# STM8S003K3 register map
Vendor: STMicroelectronics; Series: STM8S/STM8AF, low density; File version: 1.0
CPU: other r1p0, big endian, no MPU, no FPU, 4 interrupt priority bits
Registers are 8-bit, read-write, reset 0x0 unless marked. A register's access mark holds for its fields unless they carry their own. Offsets are from the block's base; [hi:lo] are bit positions; {n}, {i} and the like mark numbered series.

## CPU
Base 0x00007F00
0x00 A — Accumulator
0x01 PCE — Program counter extended
0x02 PCH — Program counter high
0x03 PCL — Program counter low
0x04 XH — X index register high
0x05 XL — X index register low
0x06 YH — Y index register high
0x07 YL — Y index register low
0x08 SPH reset 0x3 — Stack pointer high
0x09 SPL reset 0xFF — Stack pointer low
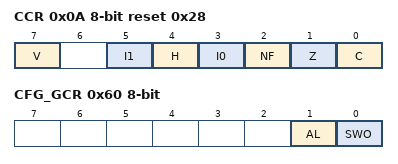
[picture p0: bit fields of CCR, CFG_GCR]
0x0A CCR reset 0x28 — Condition code register
  [7] V, [5] I1, [4] H, [3] I0, [2] NF, [1] Z, [0] C
0x60 CFG_GCR — Global configuration register
  [1] AL, [0] SWO

## DM
Base 0x00007F90
0x00 BK1RE reset 0xFF — DM breakpoint 1 register extended byte
0x01 BK1RH reset 0xFF — DM breakpoint 1 register high byte
0x02 BK1RL reset 0xFF — DM breakpoint 1 register low byte
0x03 BK2RE reset 0xFF — DM breakpoint 2 register extended byte
0x04 BK2RH reset 0xFF — DM breakpoint 2 register high byte
0x05 BK2RL reset 0xFF — DM breakpoint 2 register low byte
0x06 CR1 — DM debug module control register 1
0x07 CR2 — DM debug module control register 2
0x08 CSR1 reset 0x10 — DM debug module control/status register 1
0x09 CSR2 — DM debug module control/status register 2
0x0A ENFCTR reset 0xFF — DM enable function register

## FLASH
Base 0x0000505A
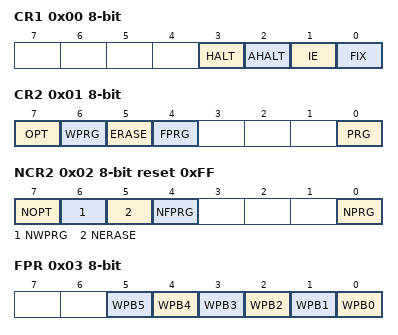
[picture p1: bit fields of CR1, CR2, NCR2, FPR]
0x00 CR1 — Flash control register 1
  [3] HALT, [2] AHALT, [1] IE, [0] FIX
0x01 CR2 — Flash control register 2
  [7] OPT, [6] WPRG, [5] ERASE, [4] FPRG, [0] PRG
0x02 NCR2 reset 0xFF — Flash complementary control register 2
  [7] NOPT, [6] NWPRG, [5] NERASE, [4] NFPRG, [0] NPRG
0x03 FPR — Flash protection register
  [n] WPB{n} (n=0..5)
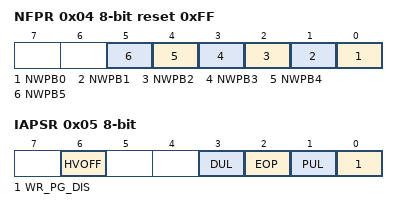
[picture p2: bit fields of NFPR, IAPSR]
0x04 NFPR reset 0xFF — Flash complementary protection register
  [n] NWPB{n} (n=0..5)
0x05 IAPSR — Flash in-application programming status register
  [6] HVOFF, [3] DUL, [2] EOP, [1] PUL, [0] WR_PG_DIS
0x08 PUKR — Flash program memory unprotection register
  [7:0] MASS_PRG
0x0A DUKR — Data EEPROM unprotection register
  [7:0] MASS_DATA

## I2C
Base 0x00005210
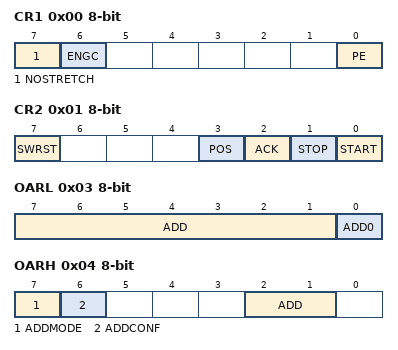
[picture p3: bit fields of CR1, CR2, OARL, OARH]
0x00 CR1 — I2C control register 1
  [7] NOSTRETCH, [6] ENGC, [0] PE
0x01 CR2 — I2C control register 2
  [7] SWRST, [3] POS, [2] ACK, [1] STOP, [0] START
0x02 FREQR — I2C frequency register
  [5:0] FREQ
0x03 OARL — I2C Own address register low
  [7:1] ADD, [0] ADD0
0x04 OARH — I2C Own address register high
  [7] ADDMODE, [6] ADDCONF, [2:1] ADD
0x06 DR — I2C data register
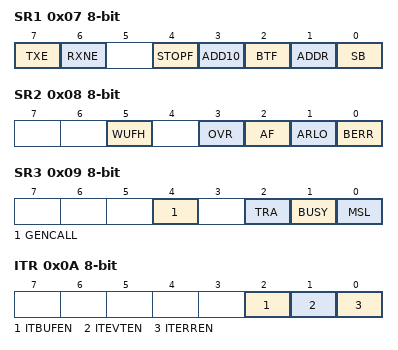
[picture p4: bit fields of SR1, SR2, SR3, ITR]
0x07 SR1 — I2C status register 1
  [7] TXE, [6] RXNE, [4] STOPF, [3] ADD10, [2] BTF, [1] ADDR, [0] SB
0x08 SR2 — I2C status register 2
  [5] WUFH, [3] OVR, [2] AF, [1] ARLO, [0] BERR
0x09 SR3 — I2C status register 3
  [4] GENCALL, [2] TRA, [1] BUSY, [0] MSL
0x0A ITR — I2C interrupt control register
  [2] ITBUFEN, [1] ITEVTEN, [0] ITERREN
0x0B CCRL — I2C Clock control register low
  [7:0] CCR
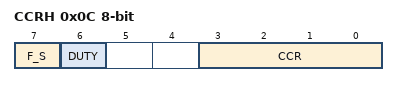
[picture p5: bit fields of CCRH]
0x0C CCRH — I2C Clock control register high
  [7] F_S, [6] DUTY, [3:0] CCR
0x0D TRISER reset 0x2 — I2C TRISE register
  [5:0] TRISE
0x0E PECR — I2C packet error checking register
  [7:0] PEC

## ITC
Base 0x000050A0
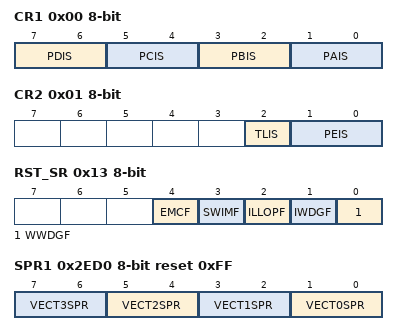
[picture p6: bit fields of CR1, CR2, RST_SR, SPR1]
0x00 CR1 — External interrupt control register 1
  [7:6] PDIS, [5:4] PCIS, [3:2] PBIS, [1:0] PAIS
0x01 CR2 — External interrupt control register 2
  [2] TLIS, [1:0] PEIS
0x13 RST_SR — Reset status register
  [4] EMCF, [3] SWIMF, [2] ILLOPF, [1] IWDGF, [0] WWDGF
0x2ED0 SPR1 reset 0xFF — Interrupt software priority register 1
  [2n+1:2n] VECT{n}SPR (n=0..3)
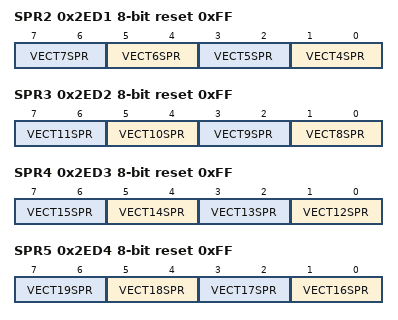
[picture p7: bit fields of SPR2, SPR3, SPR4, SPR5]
0x2ED1 SPR2 reset 0xFF — Interrupt software priority register 2
  [2n-7:2n-8] VECT{n}SPR (n=4..7)
0x2ED2 SPR3 reset 0xFF — Interrupt software priority register 3
  [2n-15:2n-16] VECT{n}SPR (n=8..11)
0x2ED3 SPR4 reset 0xFF — Interrupt software priority register 4
  [2n-23:2n-24] VECT{n}SPR (n=12..15)
0x2ED4 SPR5 reset 0xFF — Interrupt software priority register 5
  [2n-31:2n-32] VECT{n}SPR (n=16..19)
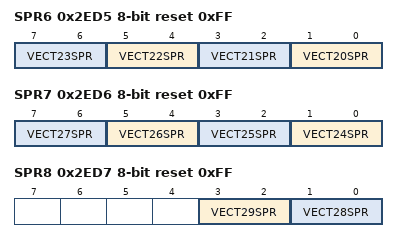
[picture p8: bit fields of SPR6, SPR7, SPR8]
0x2ED5 SPR6 reset 0xFF — Interrupt software priority register 6
  [2n-39:2n-40] VECT{n}SPR (n=20..23)
0x2ED6 SPR7 reset 0xFF — Interrupt software priority register 7
  [2n-47:2n-48] VECT{n}SPR (n=24..27)
0x2ED7 SPR8 reset 0xFF — Interrupt software priority register 8
  [3:2] VECT29SPR, [1:0] VECT28SPR
